AUTOSAR XML (schema 4-2-2)
package /UAES/ASW
  swc implementation Implementation: programming-language=C, sw-version=1.200.1, used-code-generator=Embedded Coder 7.1 (R2018b) 24-May-2018, vendor-id=0, behavior=InternalBehavior
    code-descriptors:
      code Code
        artifact-descriptors:
          short-label=Win_ComCnvTx_c, category=SWSRC
          short-label=Win_ComCnvTx_h, category=SWHDR
          short-label=rtwtypes_h, category=SWHDR
    resource consumption RsrcCons_Win_ComCnvTx
package /UAES/ASW/SwComponentTypes
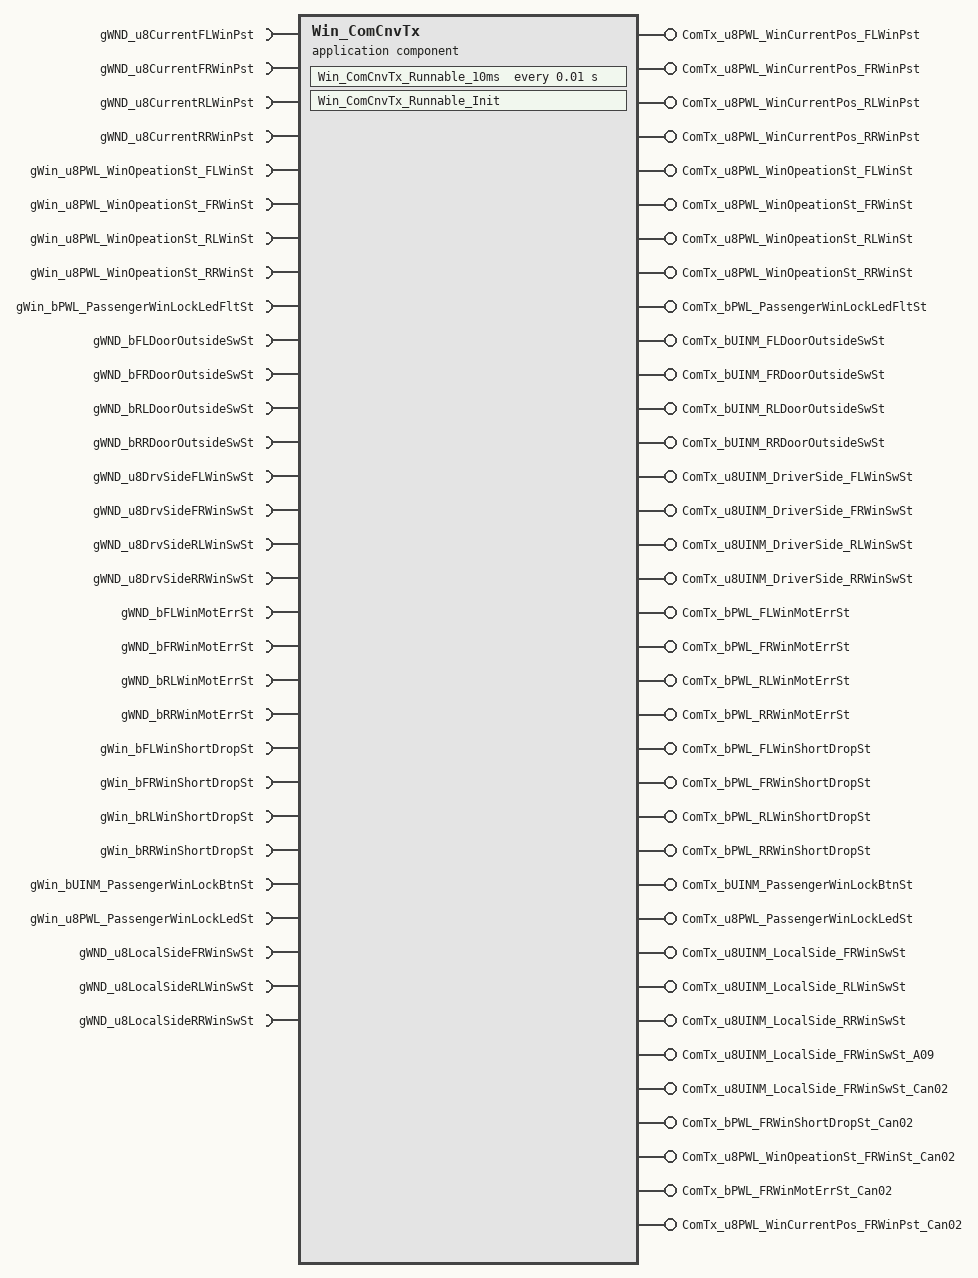
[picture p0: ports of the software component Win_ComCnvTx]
  application sw component type Win_ComCnvTx
    30 x require port:
      gWND_u8CurrentFLWinPst: nonqueued-receiver-com-spec{data-element=gWND_u8CurrentFLWinPst/Val, init-value=0}, required-interface=gWND_u8CurrentFLWinPst
      gWND_u8CurrentFRWinPst: nonqueued-receiver-com-spec{data-element=gWND_u8CurrentFRWinPst/Val, init-value=0}, required-interface=gWND_u8CurrentFRWinPst
      gWND_u8CurrentRLWinPst: nonqueued-receiver-com-spec{data-element=gWND_u8CurrentRLWinPst/Val, init-value=0}, required-interface=gWND_u8CurrentRLWinPst
      gWND_u8CurrentRRWinPst: nonqueued-receiver-com-spec{data-element=gWND_u8CurrentRRWinPst/Val, init-value=0}, required-interface=gWND_u8CurrentRRWinPst
      gWin_u8PWL_WinOpeationSt_FLWinSt: nonqueued-receiver-com-spec{data-element=gWin_u8PWL_WinOpeationSt_FLWinSt/Val, init-value=0}, required-interface=gWin_u8PWL_WinOpeationSt_FLWinSt
      gWin_u8PWL_WinOpeationSt_FRWinSt: nonqueued-receiver-com-spec{data-element=gWin_u8PWL_WinOpeationSt_FRWinSt/Val, init-value=0}, required-interface=gWin_u8PWL_WinOpeationSt_FRWinSt
      gWin_u8PWL_WinOpeationSt_RLWinSt: nonqueued-receiver-com-spec{data-element=gWin_u8PWL_WinOpeationSt_RLWinSt/Val, init-value=0}, required-interface=gWin_u8PWL_WinOpeationSt_RLWinSt
      gWin_u8PWL_WinOpeationSt_RRWinSt: nonqueued-receiver-com-spec{data-element=gWin_u8PWL_WinOpeationSt_RRWinSt/Val, init-value=0}, required-interface=gWin_u8PWL_WinOpeationSt_RRWinSt
      gWin_bPWL_PassengerWinLockLedFltSt: nonqueued-receiver-com-spec{data-element=gWin_bPWL_PassengerWinLockLedFltSt/Val, init-value=0}, required-interface=gWin_bPWL_PassengerWinLockLedFltSt
      gWND_bFLDoorOutsideSwSt: nonqueued-receiver-com-spec{data-element=gWND_bFLDoorOutsideSwSt/Val, init-value=0}, required-interface=gWND_bFLDoorOutsideSwSt
      gWND_bFRDoorOutsideSwSt: nonqueued-receiver-com-spec{data-element=gWND_bFRDoorOutsideSwSt/Val, init-value=0}, required-interface=gWND_bFRDoorOutsideSwSt
      gWND_bRLDoorOutsideSwSt: nonqueued-receiver-com-spec{data-element=gWND_bRLDoorOutsideSwSt/Val, init-value=0}, required-interface=gWND_bRLDoorOutsideSwSt
      gWND_bRRDoorOutsideSwSt: nonqueued-receiver-com-spec{data-element=gWND_bRRDoorOutsideSwSt/Val, init-value=0}, required-interface=gWND_bRRDoorOutsideSwSt
      gWND_u8DrvSideFLWinSwSt: nonqueued-receiver-com-spec{data-element=gWND_u8DrvSideFLWinSwSt/Val, init-value=0}, required-interface=gWND_u8DrvSideFLWinSwSt
      gWND_u8DrvSideFRWinSwSt: nonqueued-receiver-com-spec{data-element=gWND_u8DrvSideFRWinSwSt/Val, init-value=0}, required-interface=gWND_u8DrvSideFRWinSwSt
      gWND_u8DrvSideRLWinSwSt: nonqueued-receiver-com-spec{data-element=gWND_u8DrvSideRLWinSwSt/Val, init-value=0}, required-interface=gWND_u8DrvSideRLWinSwSt
      gWND_u8DrvSideRRWinSwSt: nonqueued-receiver-com-spec{data-element=gWND_u8DrvSideRRWinSwSt/Val, init-value=0}, required-interface=gWND_u8DrvSideRRWinSwSt
      gWND_bFLWinMotErrSt: nonqueued-receiver-com-spec{data-element=gWND_bFLWinMotErrSt/Val, init-value=0}, required-interface=gWND_bFLWinMotErrSt
      gWND_bFRWinMotErrSt: nonqueued-receiver-com-spec{data-element=gWND_bFRWinMotErrSt/Val, init-value=0}, required-interface=gWND_bFRWinMotErrSt
      gWND_bRLWinMotErrSt: nonqueued-receiver-com-spec{data-element=gWND_bRLWinMotErrSt/Val, init-value=0}, required-interface=gWND_bRLWinMotErrSt
      gWND_bRRWinMotErrSt: nonqueued-receiver-com-spec{data-element=gWND_bRRWinMotErrSt/Val, init-value=0}, required-interface=gWND_bRRWinMotErrSt
      gWin_bFLWinShortDropSt: nonqueued-receiver-com-spec{data-element=gWin_bFLWinShortDropSt/Val, init-value=0}, required-interface=gWin_bFLWinShortDropSt
      gWin_bFRWinShortDropSt: nonqueued-receiver-com-spec{data-element=gWin_bFRWinShortDropSt/Val, init-value=0}, required-interface=gWin_bFRWinShortDropSt
      gWin_bRLWinShortDropSt: nonqueued-receiver-com-spec{data-element=gWin_bRLWinShortDropSt/Val, init-value=0}, required-interface=gWin_bRLWinShortDropSt
      gWin_bRRWinShortDropSt: nonqueued-receiver-com-spec{data-element=gWin_bRRWinShortDropSt/Val, init-value=0}, required-interface=gWin_bRRWinShortDropSt
      gWin_bUINM_PassengerWinLockBtnSt: nonqueued-receiver-com-spec{data-element=gWin_bUINM_PassengerWinLockBtnSt/Val, init-value=0}, required-interface=gWin_bUINM_PassengerWinLockBtnSt
      gWin_u8PWL_PassengerWinLockLedSt: nonqueued-receiver-com-spec{data-element=gWin_u8PWL_PassengerWinLockLedSt/Val, init-value=0}, required-interface=gWin_u8PWL_PassengerWinLockLedSt
      gWND_u8LocalSideFRWinSwSt: nonqueued-receiver-com-spec{data-element=gWND_u8LocalSideFRWinSwSt/Val, init-value=0}, required-interface=gWND_u8LocalSideFRWinSwSt
      gWND_u8LocalSideRLWinSwSt: nonqueued-receiver-com-spec{data-element=gWND_u8LocalSideRLWinSwSt/Val, init-value=0}, required-interface=gWND_u8LocalSideRLWinSwSt
      gWND_u8LocalSideRRWinSwSt: nonqueued-receiver-com-spec{data-element=gWND_u8LocalSideRRWinSwSt/Val, init-value=0}, required-interface=gWND_u8LocalSideRRWinSwSt
    36 x provide port:
      ComTx_u8PWL_WinCurrentPos_FLWinPst: nonqueued-sender-com-spec{data-element=ComTx_u8PWL_WinCurrentPos_FLWinPst/Val, init-value=0}, provided-interface=ComTx_u8PWL_WinCurrentPos_FLWinPst
      ComTx_u8PWL_WinCurrentPos_FRWinPst: nonqueued-sender-com-spec{data-element=ComTx_u8PWL_WinCurrentPos_FRWinPst/Val, init-value=0}, provided-interface=ComTx_u8PWL_WinCurrentPos_FRWinPst
      ComTx_u8PWL_WinCurrentPos_RLWinPst: nonqueued-sender-com-spec{data-element=ComTx_u8PWL_WinCurrentPos_RLWinPst/Val, init-value=0}, provided-interface=ComTx_u8PWL_WinCurrentPos_RLWinPst
      ComTx_u8PWL_WinCurrentPos_RRWinPst: nonqueued-sender-com-spec{data-element=ComTx_u8PWL_WinCurrentPos_RRWinPst/Val, init-value=0}, provided-interface=ComTx_u8PWL_WinCurrentPos_RRWinPst
      ComTx_u8PWL_WinOpeationSt_FLWinSt: nonqueued-sender-com-spec{data-element=ComTx_u8PWL_WinOpeationSt_FLWinSt/Val, init-value=0}, provided-interface=ComTx_u8PWL_WinOpeationSt_FLWinSt
      ComTx_u8PWL_WinOpeationSt_FRWinSt: nonqueued-sender-com-spec{data-element=ComTx_u8PWL_WinOpeationSt_FRWinSt/Val, init-value=0}, provided-interface=ComTx_u8PWL_WinOpeationSt_FRWinSt
      ComTx_u8PWL_WinOpeationSt_RLWinSt: nonqueued-sender-com-spec{data-element=ComTx_u8PWL_WinOpeationSt_RLWinSt/Val, init-value=0}, provided-interface=ComTx_u8PWL_WinOpeationSt_RLWinSt
      ComTx_u8PWL_WinOpeationSt_RRWinSt: nonqueued-sender-com-spec{data-element=ComTx_u8PWL_WinOpeationSt_RRWinSt/Val, init-value=0}, provided-interface=ComTx_u8PWL_WinOpeationSt_RRWinSt
      ComTx_bPWL_PassengerWinLockLedFltSt: nonqueued-sender-com-spec{data-element=ComTx_bPWL_PassengerWinLockLedFltSt/Val, init-value=0}, provided-interface=ComTx_bPWL_PassengerWinLockLedFltSt
      ComTx_bUINM_FLDoorOutsideSwSt: nonqueued-sender-com-spec{data-element=ComTx_bUINM_FLDoorOutsideSwSt/Val, init-value=0}, provided-interface=ComTx_bUINM_FLDoorOutsideSwSt
      ComTx_bUINM_FRDoorOutsideSwSt: nonqueued-sender-com-spec{data-element=ComTx_bUINM_FRDoorOutsideSwSt/Val, init-value=0}, provided-interface=ComTx_bUINM_FRDoorOutsideSwSt
      ComTx_bUINM_RLDoorOutsideSwSt: nonqueued-sender-com-spec{data-element=ComTx_bUINM_RLDoorOutsideSwSt/Val, init-value=0}, provided-interface=ComTx_bUINM_RLDoorOutsideSwSt
      ComTx_bUINM_RRDoorOutsideSwSt: nonqueued-sender-com-spec{data-element=ComTx_bUINM_RRDoorOutsideSwSt/Val, init-value=0}, provided-interface=ComTx_bUINM_RRDoorOutsideSwSt
      ComTx_u8UINM_DriverSide_FLWinSwSt: nonqueued-sender-com-spec{data-element=ComTx_u8UINM_DriverSide_FLWinSwSt/Val, init-value=0}, provided-interface=ComTx_u8UINM_DriverSide_FLWinSwSt
      ComTx_u8UINM_DriverSide_FRWinSwSt: nonqueued-sender-com-spec{data-element=ComTx_u8UINM_DriverSide_FRWinSwSt/Val, init-value=0}, provided-interface=ComTx_u8UINM_DriverSide_FRWinSwSt
      ComTx_u8UINM_DriverSide_RLWinSwSt: nonqueued-sender-com-spec{data-element=ComTx_u8UINM_DriverSide_RLWinSwSt/Val, init-value=0}, provided-interface=ComTx_u8UINM_DriverSide_RLWinSwSt
      ComTx_u8UINM_DriverSide_RRWinSwSt: nonqueued-sender-com-spec{data-element=ComTx_u8UINM_DriverSide_RRWinSwSt/Val, init-value=0}, provided-interface=ComTx_u8UINM_DriverSide_RRWinSwSt
      ComTx_bPWL_FLWinMotErrSt: nonqueued-sender-com-spec{data-element=ComTx_bPWL_FLWinMotErrSt/Val, init-value=0}, provided-interface=ComTx_bPWL_FLWinMotErrSt
      ComTx_bPWL_FRWinMotErrSt: nonqueued-sender-com-spec{data-element=ComTx_bPWL_FRWinMotErrSt/Val, init-value=0}, provided-interface=ComTx_bPWL_FRWinMotErrSt
      ComTx_bPWL_RLWinMotErrSt: nonqueued-sender-com-spec{data-element=ComTx_bPWL_RLWinMotErrSt/Val, init-value=0}, provided-interface=ComTx_bPWL_RLWinMotErrSt
      ComTx_bPWL_RRWinMotErrSt: nonqueued-sender-com-spec{data-element=ComTx_bPWL_RRWinMotErrSt/Val, init-value=0}, provided-interface=ComTx_bPWL_RRWinMotErrSt
      ComTx_bPWL_FLWinShortDropSt: nonqueued-sender-com-spec{data-element=ComTx_bPWL_FLWinShortDropSt/Val, init-value=0}, provided-interface=ComTx_bPWL_FLWinShortDropSt
      ComTx_bPWL_FRWinShortDropSt: nonqueued-sender-com-spec{data-element=ComTx_bPWL_FRWinShortDropSt/Val, init-value=0}, provided-interface=ComTx_bPWL_FRWinShortDropSt
      ComTx_bPWL_RLWinShortDropSt: nonqueued-sender-com-spec{data-element=ComTx_bPWL_RLWinShortDropSt/Val, init-value=0}, provided-interface=ComTx_bPWL_RLWinShortDropSt
      ComTx_bPWL_RRWinShortDropSt: nonqueued-sender-com-spec{data-element=ComTx_bPWL_RRWinShortDropSt/Val, init-value=0}, provided-interface=ComTx_bPWL_RRWinShortDropSt
      ComTx_bUINM_PassengerWinLockBtnSt: nonqueued-sender-com-spec{data-element=ComTx_bUINM_PassengerWinLockBtnSt/Val, init-value=0}, provided-interface=ComTx_bUINM_PassengerWinLockBtnSt
      ComTx_u8PWL_PassengerWinLockLedSt: nonqueued-sender-com-spec{data-element=ComTx_u8PWL_PassengerWinLockLedSt/Val, init-value=0}, provided-interface=ComTx_u8PWL_PassengerWinLockLedSt
      ComTx_u8UINM_LocalSide_FRWinSwSt: nonqueued-sender-com-spec{data-element=ComTx_u8UINM_LocalSide_FRWinSwSt/Val, init-value=0}, provided-interface=ComTx_u8UINM_LocalSide_FRWinSwSt
      ComTx_u8UINM_LocalSide_RLWinSwSt: nonqueued-sender-com-spec{data-element=ComTx_u8UINM_LocalSide_RLWinSwSt/Val, init-value=0}, provided-interface=ComTx_u8UINM_LocalSide_RLWinSwSt
      ComTx_u8UINM_LocalSide_RRWinSwSt: nonqueued-sender-com-spec{data-element=ComTx_u8UINM_LocalSide_RRWinSwSt/Val, init-value=0}, provided-interface=ComTx_u8UINM_LocalSide_RRWinSwSt
      ComTx_u8UINM_LocalSide_FRWinSwSt_A09: nonqueued-sender-com-spec{data-element=ComTx_u8UINM_LocalSide_FRWinSwSt_A09/Val, init-value=0}, provided-interface=ComTx_u8UINM_LocalSide_FRWinSwSt_A09
      ComTx_u8UINM_LocalSide_FRWinSwSt_Can02: nonqueued-sender-com-spec{data-element=ComTx_u8UINM_LocalSide_FRWinSwSt_Can02/Val, init-value=0}, provided-interface=ComTx_u8UINM_LocalSide_FRWinSwSt_Can02
      ComTx_bPWL_FRWinShortDropSt_Can02: nonqueued-sender-com-spec{data-element=ComTx_bPWL_FRWinShortDropSt_Can02/Val, init-value=0}, provided-interface=ComTx_bPWL_FRWinShortDropSt_Can02
      ComTx_u8PWL_WinOpeationSt_FRWinSt_Can02: nonqueued-sender-com-spec{data-element=ComTx_u8PWL_WinOpeationSt_FRWinSt_Can02/Val, init-value=0}, provided-interface=ComTx_u8PWL_WinOpeationSt_FRWinSt_Can02
      ComTx_bPWL_FRWinMotErrSt_Can02: nonqueued-sender-com-spec{data-element=ComTx_bPWL_FRWinMotErrSt_Can02/Val, init-value=0}, provided-interface=ComTx_bPWL_FRWinMotErrSt_Can02
      ComTx_u8PWL_WinCurrentPos_FRWinPst_Can02: nonqueued-sender-com-spec{data-element=ComTx_u8PWL_WinCurrentPos_FRWinPst_Can02/Val, init-value=0}, provided-interface=ComTx_u8PWL_WinCurrentPos_FRWinPst_Can02
    behavior InternalBehavior: handle-termination-and-restart=NO-SUPPORT
      init event Win_ComCnvTx_InitEvent: start-on-event=Win_ComCnvTx_Runnable_Init
      timing event TMT_Win_ComCnvTx_Runnable_10ms: start-on-event=Win_ComCnvTx_Runnable_10ms, period=0.01
      runnable Win_ComCnvTx_Runnable_Init
      runnable Win_ComCnvTx_Runnable_10ms
        data-receive-point-by-arguments:
          30 x access:
            IN_gWND_bFLDoorOutsideSwSt_Val: accessed-variable=gWND_bFLDoorOutsideSwSt.Val
            IN_gWND_bFLWinMotErrSt_Val: accessed-variable=gWND_bFLWinMotErrSt.Val
            IN_gWND_bFRDoorOutsideSwSt_Val: accessed-variable=gWND_bFRDoorOutsideSwSt.Val
            IN_gWND_bFRWinMotErrSt_Val: accessed-variable=gWND_bFRWinMotErrSt.Val
            IN_gWND_bRLDoorOutsideSwSt_Val: accessed-variable=gWND_bRLDoorOutsideSwSt.Val
            IN_gWND_bRLWinMotErrSt_Val: accessed-variable=gWND_bRLWinMotErrSt.Val
            IN_gWND_bRRDoorOutsideSwSt_Val: accessed-variable=gWND_bRRDoorOutsideSwSt.Val
            IN_gWND_bRRWinMotErrSt_Val: accessed-variable=gWND_bRRWinMotErrSt.Val
            IN_gWND_u8CurrentFLWinPst_Val: accessed-variable=gWND_u8CurrentFLWinPst.Val
            IN_gWND_u8CurrentFRWinPst_Val: accessed-variable=gWND_u8CurrentFRWinPst.Val
            IN_gWND_u8CurrentRLWinPst_Val: accessed-variable=gWND_u8CurrentRLWinPst.Val
            IN_gWND_u8CurrentRRWinPst_Val: accessed-variable=gWND_u8CurrentRRWinPst.Val
            IN_gWND_u8DrvSideFLWinSwSt_Val: accessed-variable=gWND_u8DrvSideFLWinSwSt.Val
            IN_gWND_u8DrvSideFRWinSwSt_Val: accessed-variable=gWND_u8DrvSideFRWinSwSt.Val
            IN_gWND_u8DrvSideRLWinSwSt_Val: accessed-variable=gWND_u8DrvSideRLWinSwSt.Val
            IN_gWND_u8DrvSideRRWinSwSt_Val: accessed-variable=gWND_u8DrvSideRRWinSwSt.Val
            IN_gWND_u8LocalSideFRWinSwSt_Val: accessed-variable=gWND_u8LocalSideFRWinSwSt.Val
            IN_gWND_u8LocalSideRLWinSwSt_Val: accessed-variable=gWND_u8LocalSideRLWinSwSt.Val
            IN_gWND_u8LocalSideRRWinSwSt_Val: accessed-variable=gWND_u8LocalSideRRWinSwSt.Val
            IN_gWin_bFLWinShortDropSt_Val: accessed-variable=gWin_bFLWinShortDropSt.Val
            IN_gWin_bFRWinShortDropSt_Val: accessed-variable=gWin_bFRWinShortDropSt.Val
            IN_gWin_bPWL_PassengerWinLockLedFltSt_Val: accessed-variable=gWin_bPWL_PassengerWinLockLedFltSt.Val
            IN_gWin_bRLWinShortDropSt_Val: accessed-variable=gWin_bRLWinShortDropSt.Val
            IN_gWin_bRRWinShortDropSt_Val: accessed-variable=gWin_bRRWinShortDropSt.Val
            IN_gWin_bUINM_PassengerWinLockBtnSt_Val: accessed-variable=gWin_bUINM_PassengerWinLockBtnSt.Val
            IN_gWin_u8PWL_PassengerWinLockLedSt_Val: accessed-variable=gWin_u8PWL_PassengerWinLockLedSt.Val
            IN_gWin_u8PWL_WinOpeationSt_FLWinSt_Val: accessed-variable=gWin_u8PWL_WinOpeationSt_FLWinSt.Val
            IN_gWin_u8PWL_WinOpeationSt_FRWinSt_Val: accessed-variable=gWin_u8PWL_WinOpeationSt_FRWinSt.Val
            IN_gWin_u8PWL_WinOpeationSt_RLWinSt_Val: accessed-variable=gWin_u8PWL_WinOpeationSt_RLWinSt.Val
            IN_gWin_u8PWL_WinOpeationSt_RRWinSt_Val: accessed-variable=gWin_u8PWL_WinOpeationSt_RRWinSt.Val
        data-send-points:
          36 x access:
            OUT_ComTx_u8PWL_WinCurrentPos_FLWinPst_Val: accessed-variable=ComTx_u8PWL_WinCurrentPos_FLWinPst.Val
            OUT_ComTx_u8PWL_WinCurrentPos_FRWinPst_Val: accessed-variable=ComTx_u8PWL_WinCurrentPos_FRWinPst.Val
            OUT_ComTx_u8PWL_WinCurrentPos_RLWinPst_Val: accessed-variable=ComTx_u8PWL_WinCurrentPos_RLWinPst.Val
            OUT_ComTx_u8PWL_WinCurrentPos_RRWinPst_Val: accessed-variable=ComTx_u8PWL_WinCurrentPos_RRWinPst.Val
            OUT_ComTx_u8PWL_WinOpeationSt_FLWinSt_Val: accessed-variable=ComTx_u8PWL_WinOpeationSt_FLWinSt.Val
            OUT_ComTx_u8PWL_WinOpeationSt_FRWinSt_Val: accessed-variable=ComTx_u8PWL_WinOpeationSt_FRWinSt.Val
            OUT_ComTx_u8PWL_WinOpeationSt_RLWinSt_Val: accessed-variable=ComTx_u8PWL_WinOpeationSt_RLWinSt.Val
            OUT_ComTx_u8PWL_WinOpeationSt_RRWinSt_Val: accessed-variable=ComTx_u8PWL_WinOpeationSt_RRWinSt.Val
            OUT_ComTx_bPWL_PassengerWinLockLedFltSt_Val: accessed-variable=ComTx_bPWL_PassengerWinLockLedFltSt.Val
            OUT_ComTx_bUINM_FLDoorOutsideSwSt_Val: accessed-variable=ComTx_bUINM_FLDoorOutsideSwSt.Val
            OUT_ComTx_bUINM_FRDoorOutsideSwSt_Val: accessed-variable=ComTx_bUINM_FRDoorOutsideSwSt.Val
            OUT_ComTx_bUINM_RLDoorOutsideSwSt_Val: accessed-variable=ComTx_bUINM_RLDoorOutsideSwSt.Val
            OUT_ComTx_bUINM_RRDoorOutsideSwSt_Val: accessed-variable=ComTx_bUINM_RRDoorOutsideSwSt.Val
            OUT_ComTx_u8UINM_DriverSide_FLWinSwSt_Val: accessed-variable=ComTx_u8UINM_DriverSide_FLWinSwSt.Val
            OUT_ComTx_u8UINM_DriverSide_FRWinSwSt_Val: accessed-variable=ComTx_u8UINM_DriverSide_FRWinSwSt.Val
            OUT_ComTx_u8UINM_DriverSide_RLWinSwSt_Val: accessed-variable=ComTx_u8UINM_DriverSide_RLWinSwSt.Val
            OUT_ComTx_u8UINM_DriverSide_RRWinSwSt_Val: accessed-variable=ComTx_u8UINM_DriverSide_RRWinSwSt.Val
            OUT_ComTx_bPWL_FLWinMotErrSt_Val: accessed-variable=ComTx_bPWL_FLWinMotErrSt.Val
            OUT_ComTx_bPWL_FRWinMotErrSt_Val: accessed-variable=ComTx_bPWL_FRWinMotErrSt.Val
            OUT_ComTx_bPWL_RLWinMotErrSt_Val: accessed-variable=ComTx_bPWL_RLWinMotErrSt.Val
            OUT_ComTx_bPWL_RRWinMotErrSt_Val: accessed-variable=ComTx_bPWL_RRWinMotErrSt.Val
            OUT_ComTx_bPWL_FLWinShortDropSt_Val: accessed-variable=ComTx_bPWL_FLWinShortDropSt.Val
            OUT_ComTx_bPWL_FRWinShortDropSt_Val: accessed-variable=ComTx_bPWL_FRWinShortDropSt.Val
            OUT_ComTx_bPWL_RLWinShortDropSt_Val: accessed-variable=ComTx_bPWL_RLWinShortDropSt.Val
            OUT_ComTx_bPWL_RRWinShortDropSt_Val: accessed-variable=ComTx_bPWL_RRWinShortDropSt.Val
            OUT_ComTx_bUINM_PassengerWinLockBtnSt_Val: accessed-variable=ComTx_bUINM_PassengerWinLockBtnSt.Val
            OUT_ComTx_u8PWL_PassengerWinLockLedSt_Val: accessed-variable=ComTx_u8PWL_PassengerWinLockLedSt.Val
            OUT_ComTx_u8UINM_LocalSide_FRWinSwSt_Val: accessed-variable=ComTx_u8UINM_LocalSide_FRWinSwSt.Val
            OUT_ComTx_u8UINM_LocalSide_RLWinSwSt_Val: accessed-variable=ComTx_u8UINM_LocalSide_RLWinSwSt.Val
            OUT_ComTx_u8UINM_LocalSide_RRWinSwSt_Val: accessed-variable=ComTx_u8UINM_LocalSide_RRWinSwSt.Val
            OUT_ComTx_u8UINM_LocalSide_FRWinSwSt_A09_Val: accessed-variable=ComTx_u8UINM_LocalSide_FRWinSwSt_A09.Val
            OUT_ComTx_u8UINM_LocalSide_FRWinSwSt_Can02_Val: accessed-variable=ComTx_u8UINM_LocalSide_FRWinSwSt_Can02.Val
            OUT_ComTx_bPWL_FRWinShortDropSt_Can02_Val: accessed-variable=ComTx_bPWL_FRWinShortDropSt_Can02.Val
            OUT_ComTx_u8PWL_WinOpeationSt_FRWinSt_Can02_Val: accessed-variable=ComTx_u8PWL_WinOpeationSt_FRWinSt_Can02.Val
            OUT_ComTx_bPWL_FRWinMotErrSt_Can02_Val: accessed-variable=ComTx_bPWL_FRWinMotErrSt_Can02.Val
            OUT_ComTx_u8PWL_WinCurrentPos_FRWinPst_Can02_Val: accessed-variable=ComTx_u8PWL_WinCurrentPos_FRWinPst_Can02.Val
package /UAES/ASW/PortInterfaces
  66 x sender receiver interface:
    gWND_u8CurrentFLWinPst
      data Val: category=VALUE, sw-calibration-access=READ-ONLY, type=uint8
    gWND_u8CurrentFRWinPst
      data Val: category=VALUE, sw-calibration-access=READ-ONLY, type=uint8
    gWND_u8CurrentRLWinPst
      data Val: category=VALUE, sw-calibration-access=READ-ONLY, type=uint8
    gWND_u8CurrentRRWinPst
      data Val: category=VALUE, sw-calibration-access=READ-ONLY, type=uint8
    gWin_u8PWL_WinOpeationSt_FLWinSt
      data Val: category=VALUE, sw-calibration-access=READ-ONLY, type=uint8
    gWin_u8PWL_WinOpeationSt_FRWinSt
      data Val: category=VALUE, sw-calibration-access=READ-ONLY, type=uint8
    gWin_u8PWL_WinOpeationSt_RLWinSt
      data Val: category=VALUE, sw-calibration-access=READ-ONLY, type=uint8
    gWin_u8PWL_WinOpeationSt_RRWinSt
      data Val: category=VALUE, sw-calibration-access=READ-ONLY, type=uint8
    gWin_bPWL_PassengerWinLockLedFltSt
      data Val: category=VALUE, sw-calibration-access=READ-ONLY, type=boolean
    gWND_bFLDoorOutsideSwSt
      data Val: category=VALUE, sw-calibration-access=READ-ONLY, type=boolean
    gWND_bFRDoorOutsideSwSt
      data Val: category=VALUE, sw-calibration-access=READ-ONLY, type=boolean
    gWND_bRLDoorOutsideSwSt
      data Val: category=VALUE, sw-calibration-access=READ-ONLY, type=boolean
    gWND_bRRDoorOutsideSwSt
      data Val: category=VALUE, sw-calibration-access=READ-ONLY, type=boolean
    gWND_u8DrvSideFLWinSwSt
      data Val: category=VALUE, sw-calibration-access=READ-ONLY, type=uint8
    gWND_u8DrvSideFRWinSwSt
      data Val: category=VALUE, sw-calibration-access=READ-ONLY, type=uint8
    gWND_u8DrvSideRLWinSwSt
      data Val: category=VALUE, sw-calibration-access=READ-ONLY, type=uint8
    gWND_u8DrvSideRRWinSwSt
      data Val: category=VALUE, sw-calibration-access=READ-ONLY, type=uint8
    gWND_bFLWinMotErrSt
      data Val: category=VALUE, sw-calibration-access=READ-ONLY, type=boolean
    gWND_bFRWinMotErrSt
      data Val: category=VALUE, sw-calibration-access=READ-ONLY, type=boolean
    gWND_bRLWinMotErrSt
      data Val: category=VALUE, sw-calibration-access=READ-ONLY, type=boolean
    gWND_bRRWinMotErrSt
      data Val: category=VALUE, sw-calibration-access=READ-ONLY, type=boolean
    gWin_bFLWinShortDropSt
      data Val: category=VALUE, sw-calibration-access=READ-ONLY, type=boolean
    gWin_bFRWinShortDropSt
      data Val: category=VALUE, sw-calibration-access=READ-ONLY, type=boolean
    gWin_bRLWinShortDropSt
      data Val: category=VALUE, sw-calibration-access=READ-ONLY, type=boolean
    gWin_bRRWinShortDropSt
      data Val: category=VALUE, sw-calibration-access=READ-ONLY, type=boolean
    gWin_bUINM_PassengerWinLockBtnSt
      data Val: category=VALUE, sw-calibration-access=READ-ONLY, type=boolean
    gWin_u8PWL_PassengerWinLockLedSt
      data Val: category=VALUE, sw-calibration-access=READ-ONLY, type=uint8
    gWND_u8LocalSideFRWinSwSt
      data Val: category=VALUE, sw-calibration-access=READ-ONLY, type=uint8
    gWND_u8LocalSideRLWinSwSt
      data Val: category=VALUE, sw-calibration-access=READ-ONLY, type=uint8
    gWND_u8LocalSideRRWinSwSt
      data Val: category=VALUE, sw-calibration-access=READ-ONLY, type=uint8
    ComTx_u8PWL_WinCurrentPos_FLWinPst
      data Val: category=VALUE, sw-calibration-access=READ-ONLY, type=uint8
    ComTx_u8PWL_WinCurrentPos_FRWinPst
      data Val: category=VALUE, sw-calibration-access=READ-ONLY, type=uint8
    ComTx_u8PWL_WinCurrentPos_RLWinPst
      data Val: category=VALUE, sw-calibration-access=READ-ONLY, type=uint8
    ComTx_u8PWL_WinCurrentPos_RRWinPst
      data Val: category=VALUE, sw-calibration-access=READ-ONLY, type=uint8
    ComTx_u8PWL_WinOpeationSt_FLWinSt
      data Val: category=VALUE, sw-calibration-access=READ-ONLY, type=uint8
    ComTx_u8PWL_WinOpeationSt_FRWinSt
      data Val: category=VALUE, sw-calibration-access=READ-ONLY, type=uint8
    ComTx_u8PWL_WinOpeationSt_RLWinSt
      data Val: category=VALUE, sw-calibration-access=READ-ONLY, type=uint8
    ComTx_u8PWL_WinOpeationSt_RRWinSt
      data Val: category=VALUE, sw-calibration-access=READ-ONLY, type=uint8
    ComTx_bPWL_PassengerWinLockLedFltSt
      data Val: category=VALUE, sw-calibration-access=READ-ONLY, type=boolean
    ComTx_bUINM_FLDoorOutsideSwSt
      data Val: category=VALUE, sw-calibration-access=READ-ONLY, type=boolean
    ComTx_bUINM_FRDoorOutsideSwSt
      data Val: category=VALUE, sw-calibration-access=READ-ONLY, type=boolean
    ComTx_bUINM_RLDoorOutsideSwSt
      data Val: category=VALUE, sw-calibration-access=READ-ONLY, type=boolean
    ComTx_bUINM_RRDoorOutsideSwSt
      data Val: category=VALUE, sw-calibration-access=READ-ONLY, type=boolean
    ComTx_u8UINM_DriverSide_FLWinSwSt
      data Val: category=VALUE, sw-calibration-access=READ-ONLY, type=uint8
    ComTx_u8UINM_DriverSide_FRWinSwSt
      data Val: category=VALUE, sw-calibration-access=READ-ONLY, type=uint8
    ComTx_u8UINM_DriverSide_RLWinSwSt
      data Val: category=VALUE, sw-calibration-access=READ-ONLY, type=uint8
    ComTx_u8UINM_DriverSide_RRWinSwSt
      data Val: category=VALUE, sw-calibration-access=READ-ONLY, type=uint8
    ComTx_bPWL_FLWinMotErrSt
      data Val: category=VALUE, sw-calibration-access=READ-ONLY, type=boolean
    ComTx_bPWL_FRWinMotErrSt
      data Val: category=VALUE, sw-calibration-access=READ-ONLY, type=boolean
    ComTx_bPWL_RLWinMotErrSt
      data Val: category=VALUE, sw-calibration-access=READ-ONLY, type=boolean
    ComTx_bPWL_RRWinMotErrSt
      data Val: category=VALUE, sw-calibration-access=READ-ONLY, type=boolean
    ComTx_bPWL_FLWinShortDropSt
      data Val: category=VALUE, sw-calibration-access=READ-ONLY, type=boolean
    ComTx_bPWL_FRWinShortDropSt
      data Val: category=VALUE, sw-calibration-access=READ-ONLY, type=boolean
    ComTx_bPWL_RLWinShortDropSt
      data Val: category=VALUE, sw-calibration-access=READ-ONLY, type=boolean
    ComTx_bPWL_RRWinShortDropSt
      data Val: category=VALUE, sw-calibration-access=READ-ONLY, type=boolean
    ComTx_bUINM_PassengerWinLockBtnSt
      data Val: category=VALUE, sw-calibration-access=READ-ONLY, type=boolean
    ComTx_u8PWL_PassengerWinLockLedSt
      data Val: category=VALUE, sw-calibration-access=READ-ONLY, type=uint8
    ComTx_u8UINM_LocalSide_FRWinSwSt
      data Val: category=VALUE, sw-calibration-access=READ-ONLY, type=uint8
    ComTx_u8UINM_LocalSide_RLWinSwSt
      data Val: category=VALUE, sw-calibration-access=READ-ONLY, type=uint8
    ComTx_u8UINM_LocalSide_RRWinSwSt
      data Val: category=VALUE, sw-calibration-access=READ-ONLY, type=uint8
    ComTx_u8UINM_LocalSide_FRWinSwSt_A09
      data Val: category=VALUE, sw-calibration-access=READ-ONLY, type=uint8
    ComTx_u8UINM_LocalSide_FRWinSwSt_Can02
      data Val: category=VALUE, sw-calibration-access=READ-ONLY, type=uint8
    ComTx_bPWL_FRWinShortDropSt_Can02
      data Val: category=VALUE, sw-calibration-access=READ-ONLY, type=boolean
    ComTx_u8PWL_WinOpeationSt_FRWinSt_Can02
      data Val: category=VALUE, sw-calibration-access=READ-ONLY, type=uint8
    ComTx_bPWL_FRWinMotErrSt_Can02
      data Val: category=VALUE, sw-calibration-access=READ-ONLY, type=boolean
    ComTx_u8PWL_WinCurrentPos_FRWinPst_Can02
      data Val: category=VALUE, sw-calibration-access=READ-ONLY, type=uint8
